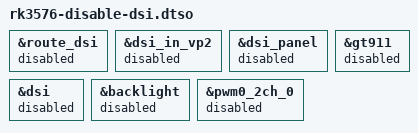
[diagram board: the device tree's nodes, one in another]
// SPDX-License-Identifier: (GPL-2.0+ OR MIT)
/dts-v1/;
/plugin/;

/*
 * Disable the on-board MIPI-DSI display path so DRM exposes HDMI/DP only.
 * Keep the shared mipidcphy0 PHY at its base-DTB status: CSI cameras also
 * use it, so disabling a display must not disable their PHY provider.
 */

&route_dsi {
	status = "disabled";
};

&dsi_in_vp2 {
	status = "disabled";
};

&dsi_panel {
	status = "disabled";
};

&gt911 {
	status = "disabled";
};

&dsi {
	status = "disabled";
};

&backlight {
	status = "disabled";
};

&pwm0_2ch_0 {
	status = "disabled";
};
